VERSION ""

NS_ :

BS_:

BU_:

BO_ 915 gear: 8 Vector__XXX
 SG_ gear_status : 24|6@1+ (1,0) [0|0] "" Vector__XXX

BO_ 1753 parking_break: 7 Vector__XXX
 SG_ parking_breake_button : 19|1@1+ (1,0) [0|0] "" Vector__XXX
 SG_ parking_break_status : 20|1@1+ (1,0) [0|0] "" Vector__XXX

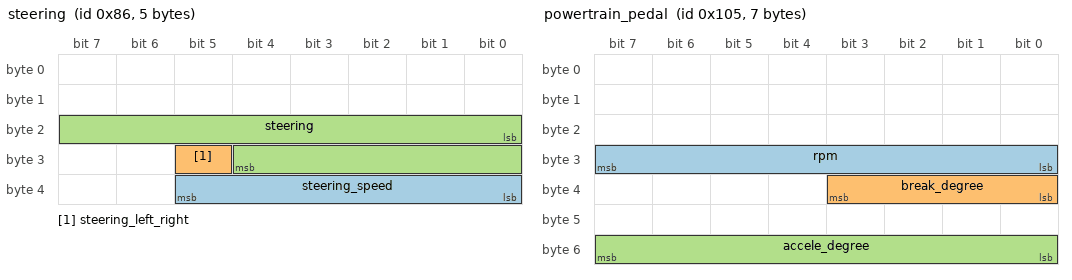
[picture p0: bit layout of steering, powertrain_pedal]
BO_ 134 steering: 5 Vector__XXX
 SG_ steering_speed : 32|6@1+ (1,0) [0|0] "" Vector__XXX
 SG_ steering_left_right : 29|1@1+ (1,0) [0|0] "" Vector__XXX
 SG_ steering : 16|13@1+ (0.1,0) [-819.2|819.1] "" Vector__XXX

BO_ 261 powertrain_pedal: 7 Vector__XXX
 SG_ rpm : 24|8@1+ (65.3846153846154,200) [0|0] "" Vector__XXX
 SG_ break_degree : 32|4@1+ (1,0) [0|0] "" Vector__XXX
 SG_ accele_degree : 48|8@1+ (0.5,0) [0|100] "" Vector__XXX
